# YTM32B1MD2 register map
Vendor: YTMicro; File version: 1.0
CPU: CM33 r0p4, little endian, MPU, FPU, 2 interrupt priority bits
Registers are 32-bit, read-write, reset 0x0 unless marked. A register's access mark holds for its fields unless they carry their own. Offsets are from the block's base; [hi:lo] are bit positions.

## CACHE — Cache Controller and Cache Array
Base 0xE0080000; register names take the prefix CACHE_
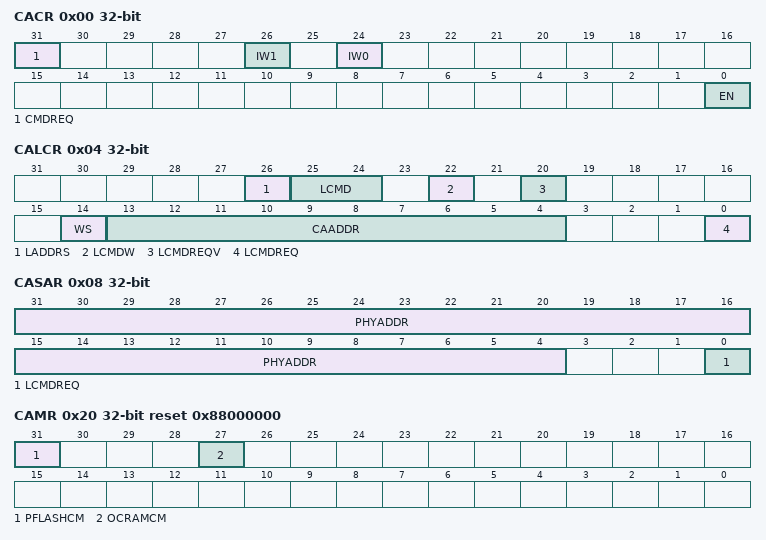
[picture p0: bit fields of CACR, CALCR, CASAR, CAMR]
0x00 CACR
  [31] CMDREQ — Initiate cache cperation command request. Setting this bit initiates the cache command indicated by bits 26,24. Reading this bit indicates if a command is active
    0=Write: no effect. Read: no cache command active.; 1=Write: initiate command indicated by bits 26,24. Read: cache command active.
  [26] IW1 — Invalidate way 1 operation
    0=No operation; 1=When setting CMDREQ bit, invalidate all lines in way 1
  [24] IW0 — Invalidate way 0 operation
    0=No operation; 1=When setting CMDREQ bit, invalidate all lines in way 0
  [0] EN — Enable Cache
    0=Cache is disable; 1=Cache is enable
0x04 CALCR
  [26] LADDRS — When using the cache address, the way must also be specified in CALCR[WS]. When using the physical address, both ways are searched and the command is performed only if a hit.
    0=Cache address; 1=Physical address
  [25:24] LCMD — Line command
    1=Invalidate
  [22] LCMDW — Indicates the way used by the line command.Only applies if valid bit LCMDREQV = 1.
  [20] LCMDREQV — If command used cache address and way, then this bit shows the initial state of the valid bit. If command used physical address and a hit, then this bit shows the initial state of the valid bit. If a miss, this bit reads zero.
  [14] WS — Select the way for line commands
    0=Way 0; 1=Way 1
  [13:4] CAADDR — Cache address to access cache tag array.
  [0] LCMDREQ — Initiate cache line command request. Setting this bit initiates the cache line command indicated by bits 26-24. Reading this bit indicates if a line command is active. This bit stays set until the command completes. Writing zero has no effect. This bit is shared with CASAR[LCMDREQ].
    0=Write: no effect. Read: no line command active.; 1=Write: initiate line command indicated by bits 26-24. Read: line command active.
0x08 CASAR
  [31:4] PHYADDR — PHYADDR represents bits [31:4] of the system address. CASAR[31:11] bits are used for tag compare. CASAR[10:4] bits are used to access the tag arrays.
  [0] LCMDREQ — Initiate Cache Line Command. Setting this bit initiates the cache line command indicated by bits 26-24. Reading this bit indicates if a line command is active. This bit stays set until the command completes. Writing zero has no effect. This bit is shared with CALCR[LCMDREQ].
    0=Write: no effect. Read: no line command active.; 1=Write: initiate line command indicated by bits CALCR[26:24]. Read: line command active.
0x20 CAMR reset 0x88000000
  [31] PFLASHCM — Controls the cache mode of PFlash. It's default 1b after system reset. Once it's been cleared, it can't be set again until next reset.
    0=Non-cacheable; 1=Write-through
  [27] OCRAMCM — Controls the cache mode of OCRAM
    0=Write-through; 1=Non-cacheable
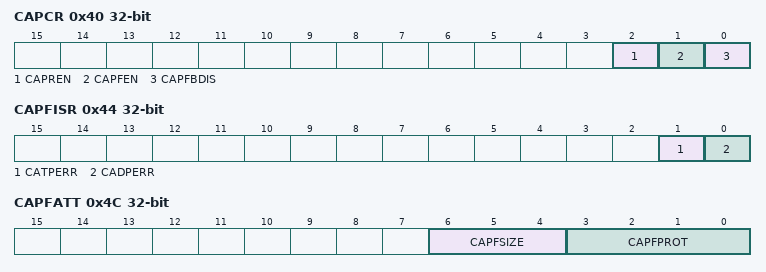
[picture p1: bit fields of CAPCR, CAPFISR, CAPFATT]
0x40 CAPCR
  [2] CAPREN — Enable Cache Parity Reporting
    0=Disable cache parity reporting; 1=Enable cache parity reporting
  [1] CAPFEN — Enable Cache Parity Fault
    0=Disable cache parity fault; 1=Enable cache parity fault
  [0] CAPFBDIS — Disable Cache Parity Fault Bus Error
    0=Enable cache parity fault bus error; 1=Disable cache parity fault bus error
0x44 CAPFISR
  [1] CATPERR — Cache Tag Parity Error Status
    0=No cache tag parity error has occurred; 1=Cache tag parity error has occurred. This bit is cleared by writing 1 to it.
  [0] CADPERR — Cache Data Parity Error Status
    0=No cache data parity error has occurred; 1=Cache data parity error has occurred. This bit is cleared by writing 1 to it.
0x48 CAPFADDR ro
  [31:0] CAPFADDR rw — Cache Parity Fault Address
0x4C CAPFATT ro
  [6:4] CAPFSIZE rw — Cache Parity Fault Access Size
    0=Byte access; 1=Half word access; 2=Word access
  [3:0] CAPFPROT rw — Cache Parity Fault Access Type. HPROT[0] 0: Opcode fetch 1: Data access HPROT[1] 0: User access 1: Privileged access HPROT[2] 0: Non-bufferable 1: Bufferable HPROT[3] 0: Non-cacheable 1: Cacheable
0x54 CAPFDAT ro
  [31:0] CAPFDAT rw — Cache Parity Fault Read Data
